# AT90USB1286 device description
Architecture: AVR8; Family: megaAVR
Registers are 8-bit, access not given, no defined reset value unless marked. A register's access mark holds for its fields unless they carry their own. Offsets are from the block's base; [hi:lo] are bit positions; {n}, {i} and the like mark numbered series; 'fields as' and 'values as' point back to an identical list.

## LOCKBIT — Lockbits
Instances: LOCKBIT 0 in lockbits
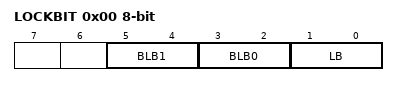
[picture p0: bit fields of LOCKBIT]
0x00 LOCKBIT
  [5:4] BLB1 — Boot Loader Protection Mode
    0=LPM_SPM_DISABLE (LPM and SPM prohibited in Boot Section); 1=LPM_DISABLE (LPM prohibited in Boot Section); 2=SPM_DISABLE (SPM prohibited in Boot Section); 3=NO_LOCK (No lock on SPM and LPM in Boot Section)
  [3:2] BLB0 — Boot Loader Protection Mode
    0=LPM_SPM_DISABLE (LPM and SPM prohibited in Application Section); 1=LPM_DISABLE (LPM prohibited in Application Section); 2=SPM_DISABLE (SPM prohibited in Application Section); 3=NO_LOCK (No lock on SPM and LPM in Application Section)
  [1:0] LB — Memory Lock
    0=PROG_VER_DISABLED (Further programming and verification disabled); 2=PROG_DISABLED (Further programming disabled); 3=NO_LOCK (No memory lock features enabled)

## WDT — Watchdog Timer
Instances: WDT 0x00
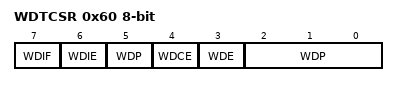
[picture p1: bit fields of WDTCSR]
0x60 WDTCSR — Watchdog Timer Control Register
  [7] WDIF — Watchdog Timeout Interrupt Flag
  [6] WDIE — Watchdog Timeout Interrupt Enable
  [4] WDCE — Watchdog Change Enable
  [3] WDE — Watch Dog Enable
  [5,2:0] WDP — Watchdog Timer Prescaler Bits
    0=Oscillator Cycles 2K; 1=Oscillator Cycles 4K; 2=Oscillator Cycles 8K; 3=Oscillator Cycles 16K; 4=Oscillator Cycles 32K; 5=Oscillator Cycles 64K; 6=Oscillator Cycles 128K; 7=Oscillator Cycles 256K; 8=Oscillator Cycles 512K; 9=Oscillator Cycles 1024K

## PORTA — I/O Port
Instances: PORTA 0x00
0x20 PINA — Port A Input Pins
0x21 DDRA — Port A Data Direction Register
0x22 PORTA — Port A Data Register

## PORTB — I/O Port
Instances: PORTB 0x00
0x23 PINB — Port B Input Pins
0x24 DDRB — Port B Data Direction Register
0x25 PORTB — Port B Data Register

## PORTC — I/O Port
Instances: PORTC 0x00
0x26 PINC — Port C Input Pins
0x27 DDRC — Port C Data Direction Register
0x28 PORTC — Port C Data Register

## PORTD — I/O Port
Instances: PORTD 0x00
0x29 PIND — Port D Input Pins
0x2A DDRD — Port D Data Direction Register
0x2B PORTD — Port D Data Register

## PORTE — I/O Port
Instances: PORTE 0x00
0x2C PINE — Input Pins, Port E
0x2D DDRE — Data Direction Register, Port E
0x2E PORTE — Data Register, Port E

## PORTF — I/O Port
Instances: PORTF 0x00
0x2F PINF — Input Pins, Port F
0x30 DDRF — Data Direction Register, Port F
0x31 PORTF — Data Register, Port F

## CPU — CPU Registers
Instances: CPU 0x00
Parameters: CORE_VERSION=V3
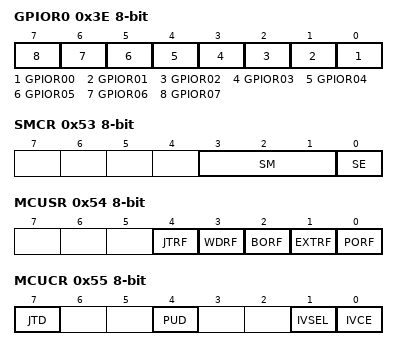
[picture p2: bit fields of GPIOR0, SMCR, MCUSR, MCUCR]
0x3E GPIOR0 — General Purpose IO Register 0
  [n] GPIOR{n:02} (n=0..7) — General Purpose IO Register 0 bit {n}
0x4A GPIOR1 — General Purpose IO Register 1
  [7:0] GPIOR (bit 10 of the value upward) — General Purpose IO Register 1 bis
0x4B GPIOR2 — General Purpose IO Register 2
  [7:0] GPIOR (bit 20 of the value upward) — General Purpose IO Register 2 bis
0x53 SMCR — Sleep Mode Control Register
  [3:1] SM — Sleep Mode Select bits
    0=IDLE; 1=ADC (ADC Noise Reduction (If Available)); 2=PDOWN (Power Down); 3=PSAVE (Power Save); 6=STDBY (Standby); 7=ESTDBY (Extended Standby)
  [0] SE — Sleep Enable
0x54 MCUSR — MCU Status Register
  [4] JTRF — JTAG Reset Flag
  [3] WDRF — Watchdog Reset Flag
  [2] BORF — Brown-out Reset Flag
  [1] EXTRF — External Reset Flag
  [0] PORF — Power-on reset flag
0x55 MCUCR — MCU Control Register
  [7] JTD — JTAG Interface Disable
  [4] PUD — Pull-up disable
  [1] IVSEL — Interrupt Vector Select
  [0] IVCE — Interrupt Vector Change Enable
0x5B RAMPZ bits used 0 — RAM Page Z Select Register
0x5C EIND bits used 0 — Extended Indirect Register
0x5D SP 16-bit — Stack Pointer
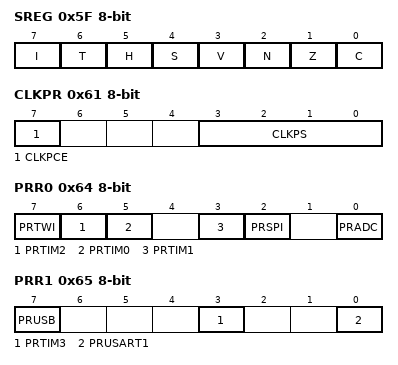
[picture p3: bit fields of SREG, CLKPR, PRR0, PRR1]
0x5F SREG — Status Register
  [7] I — Global Interrupt Enable
  [6] T — Bit Copy Storage
  [5] H — Half Carry Flag
  [4] S — Sign Bit
  [3] V — Two's Complement Overflow Flag
  [2] N — Negative Flag
  [1] Z — Zero Flag
  [0] C — Carry Flag
0x61 CLKPR
  [7] CLKPCE
  [3:0] CLKPS
    0=1; 1=2; 2=4; 3=8; 4=16; 5=32; 6=64; 7=128; 8=256
0x64 PRR0 — Power Reduction Register0
  [7] PRTWI — Power Reduction TWI
  [6] PRTIM2 — Power Reduction Timer/Counter2
  [5] PRTIM0 — Power Reduction Timer/Counter0
  [3] PRTIM1 — Power Reduction Timer/Counter1
  [2] PRSPI — Power Reduction Serial Peripheral Interface
  [0] PRADC — Power Reduction ADC
0x65 PRR1 — Power Reduction Register1
  [7] PRUSB — Power Reduction USB
  [3] PRTIM3 — Power Reduction Timer/Counter3
  [0] PRUSART1 — Power Reduction USART1
0x66 OSCCAL — Oscillator Calibration Value
  [7:0] OSCCAL — Oscillator Calibration
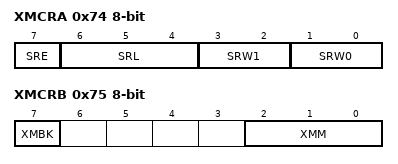
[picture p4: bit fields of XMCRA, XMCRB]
0x74 XMCRA — External Memory Control Register A
  [7] SRE — External SRAM Enable
  [6:4] SRL — Wait state page limit
    0=LS = N/A, US = 0x1100 - 0xFFFF; 1=LS = 0x2100 - 0x1FFF, US = 0x2000 - 0xFFFF; 2=LS = 0x2100 - 0x3FFF, US = 0x4000 - 0xFFFF; 3=LS = 0x2100 - 0x5FFF, US = 0x6000 - 0xFFFF; 4=LS = 0x2100 - 0x7FFF, US = 0x8000 - 0xFFFF; 5=LS = 0x2100 - 0x9FFF, US = 0xA000 - 0xFFFF; 6=LS = 0x2100 - 0xBFFF, US = 0xC000 - 0xFFFF; 7=LS = 0x2100 - 0xDFFF, US = 0xE000 - 0xFFFF
  [3:2] SRW1 — Wait state select bit upper page
    0=No wait-states; 1=Wait one cycle during read/write strobe; 2=Wait two cycles during read/write strobe; 3=Wait two cycles during read/write and wait one cycle before driving out new address
  [1:0] SRW0 — Wait state select bit lower page
    values as SRW1
0x75 XMCRB — External Memory Control Register B
  [7] XMBK — External Memory Bus Keeper Enable
  [2:0] XMM — External Memory High Mask
    0=None; 1=Px7; 2=Px7-Px6; 3=Px7-Px5; 4=Px7-Px4; 5=Px7-Px3; 6=Px7-Px2; 7=Full Port X
Value list OSCCAL_VALUE_ADDRESSES: 0=8_0_MHz
